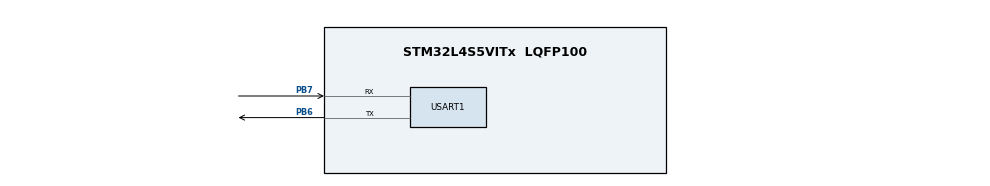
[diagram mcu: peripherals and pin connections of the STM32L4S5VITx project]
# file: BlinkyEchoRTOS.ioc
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FREERTOS.Tasks01=sendEcho,0,128,StartSendEcho,Default,NULL,Dynamic,NULL,NULL
FREERTOS.configUSE_NEWLIB_REENTRANT=1
Mcu.Family=STM32L4
Mcu.Name=STM32L4S5VITx
Mcu.Package=LQFP100
NVIC.PriorityGroup=NVIC_PRIORITYGROUP_4
NVIC.TIM6_DAC_IRQn=true\:15\:0\:false\:false\:true\:false\:false\:true\:true
NVIC.TimeBase=TIM6_DAC_IRQn
NVIC.TimeBaseIP=TIM6
NVIC.USART1_IRQn=true\:5\:0\:false\:false\:true\:true\:true\:true\:true
PB6.Mode=Asynchronous
PB6.Signal=USART1_TX
PB7.Mode=Asynchronous
PB7.Signal=USART1_RX
ProjectManager.HeapSize=0x200
ProjectManager.StackSize=0x400
ProjectManager.TargetToolchain=STM32CubeIDE
RCC.HSE_VALUE=8000000
RCC.HSI48_VALUE=48000000
RCC.HSI_VALUE=16000000
RCC.LSE_VALUE=32768
RCC.MSI_VALUE=4000000
RCC.VCOOutputFreq_Value=32000000
USART1.VirtualMode-Asynchronous=VM_ASYNC
VP_FREERTOS_VS_CMSIS_V1.Mode=CMSIS_V1
VP_SYS_VS_tim6.Mode=TIM6
board=custom

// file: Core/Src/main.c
/* USER CODE BEGIN Header */
/**
  ******************************************************************************
  * @file           : main.c
  * @brief          : Main program body
  ******************************************************************************
  * @attention
  *
  * Copyright (c) 2023 STMicroelectronics.
  * All rights reserved.
  *
  * This software is licensed under terms that can be found in the LICENSE file
  * in the root directory of this software component.
  * If no LICENSE file comes with this software, it is provided AS-IS.
  *
  ******************************************************************************
  */
/* USER CODE END Header */
#include "main.h"
#include "cmsis_os.h"

/* USER CODE BEGIN PD */
#define FLGPTN 0x00000001
/* USER CODE END PD */

UART_HandleTypeDef huart1;

osThreadId sendEchoHandle;
/* USER CODE BEGIN PV */
uint8_t UART1_rxBuffer[1];
/* USER CODE END PV */

void SystemClock_Config(void);
static void MX_GPIO_Init(void);
static void MX_USART1_UART_Init(void);
void StartSendEcho(void const * argument);

int main(void)
{

  /* MCU Configuration--------------------------------------------------------*/

  /* Reset of all peripherals, Initializes the Flash interface and the Systick. */
  HAL_Init();

  /* Configure the system clock */
  SystemClock_Config();

  /* Initialize all configured peripherals */
  MX_GPIO_Init();
  MX_USART1_UART_Init();
  /* USER CODE BEGIN 2 */
  HAL_UART_Receive_IT(&huart1, UART1_rxBuffer, sizeof(UART1_rxBuffer));
  /* USER CODE END 2 */

  /* Create the thread(s) */
  /* definition and creation of sendEcho */
  osThreadDef(sendEcho, StartSendEcho, osPriorityNormal, 0, 128);
  sendEchoHandle = osThreadCreate(osThread(sendEcho), NULL);

  /* Start scheduler */
  osKernelStart();

  /* We should never get here as control is now taken by the scheduler */
  /* Infinite loop */
  while (1)
  {

  }
}

void SystemClock_Config(void)
{
  RCC_OscInitTypeDef RCC_OscInitStruct = {0};
  RCC_ClkInitTypeDef RCC_ClkInitStruct = {0};

  /** Configure the main internal regulator output voltage
  */
  if (HAL_PWREx_ControlVoltageScaling(PWR_REGULATOR_VOLTAGE_SCALE1) != HAL_OK)
  {
    Error_Handler();
  }

  /** Initializes the RCC Oscillators according to the specified parameters
  * in the RCC_OscInitTypeDef structure.
  */
  RCC_OscInitStruct.OscillatorType = RCC_OSCILLATORTYPE_MSI;
  RCC_OscInitStruct.MSIState = RCC_MSI_ON;
  RCC_OscInitStruct.MSICalibrationValue = 0;
  RCC_OscInitStruct.MSIClockRange = RCC_MSIRANGE_6;
  RCC_OscInitStruct.PLL.PLLState = RCC_PLL_NONE;
  if (HAL_RCC_OscConfig(&RCC_OscInitStruct) != HAL_OK)
  {
    Error_Handler();
  }

  /** Initializes the CPU, AHB and APB buses clocks
  */
  RCC_ClkInitStruct.ClockType = RCC_CLOCKTYPE_HCLK|RCC_CLOCKTYPE_SYSCLK
                              |RCC_CLOCKTYPE_PCLK1|RCC_CLOCKTYPE_PCLK2;
  RCC_ClkInitStruct.SYSCLKSource = RCC_SYSCLKSOURCE_MSI;
  RCC_ClkInitStruct.AHBCLKDivider = RCC_SYSCLK_DIV1;
  RCC_ClkInitStruct.APB1CLKDivider = RCC_HCLK_DIV1;
  RCC_ClkInitStruct.APB2CLKDivider = RCC_HCLK_DIV1;

  if (HAL_RCC_ClockConfig(&RCC_ClkInitStruct, FLASH_LATENCY_0) != HAL_OK)
  {
    Error_Handler();
  }
}

static void MX_USART1_UART_Init(void)
{

  huart1.Instance = USART1;
  huart1.Init.BaudRate = 115200;
  huart1.Init.WordLength = UART_WORDLENGTH_8B;
  huart1.Init.StopBits = UART_STOPBITS_1;
  huart1.Init.Parity = UART_PARITY_NONE;
  huart1.Init.Mode = UART_MODE_TX_RX;
  huart1.Init.HwFlowCtl = UART_HWCONTROL_NONE;
  huart1.Init.OverSampling = UART_OVERSAMPLING_16;
  huart1.Init.OneBitSampling = UART_ONE_BIT_SAMPLE_DISABLE;
  huart1.Init.ClockPrescaler = UART_PRESCALER_DIV1;
  huart1.AdvancedInit.AdvFeatureInit = UART_ADVFEATURE_NO_INIT;
  if (HAL_UART_Init(&huart1) != HAL_OK)
  {
    Error_Handler();
  }
  if (HAL_UARTEx_SetTxFifoThreshold(&huart1, UART_TXFIFO_THRESHOLD_1_8) != HAL_OK)
  {
    Error_Handler();
  }
  if (HAL_UARTEx_SetRxFifoThreshold(&huart1, UART_RXFIFO_THRESHOLD_1_8) != HAL_OK)
  {
    Error_Handler();
  }
  if (HAL_UARTEx_DisableFifoMode(&huart1) != HAL_OK)
  {
    Error_Handler();
  }

}

static void MX_GPIO_Init(void)
{

  /* GPIO Ports Clock Enable */
  __HAL_RCC_GPIOB_CLK_ENABLE();

}

/* USER CODE BEGIN 4 */
void HAL_UART_RxCpltCallback(UART_HandleTypeDef *huart)
{

	osSignalSet(sendEchoHandle, FLGPTN);
	HAL_UART_Receive_IT(&huart1, UART1_rxBuffer, sizeof(UART1_rxBuffer));
}
/* USER CODE END 4 */

void StartSendEcho(void const * argument)
{
  /* USER CODE BEGIN 5 */
  /* Infinite loop */
  for(;;)
  {
	  osEvent event = osSignalWait(FLGPTN, osWaitForever);
	  	    if (event.status == osEventSignal && event.value.signals == FLGPTN)
	  	    {
	  	    	HAL_UART_Transmit(&huart1, UART1_rxBuffer, 1, 10);
	  	    }

    osDelay(1);
  }
  /* USER CODE END 5 */
}

void HAL_TIM_PeriodElapsedCallback(TIM_HandleTypeDef *htim)
{
  if (htim->Instance == TIM6) {
    HAL_IncTick();
  }
}

void Error_Handler(void)
{
  __disable_irq();
  while (1)
  {
  }
}
